# SERDES_10G0 register map
Vendor: Texas Instruments
Registers are 32-bit, access per field, reset 0x0 unless marked. A register's access mark holds for its fields unless they carry their own. Offsets are as the file gives them; [hi:lo] are bit positions.

## SERDES_10G0 (part 6 of 8)
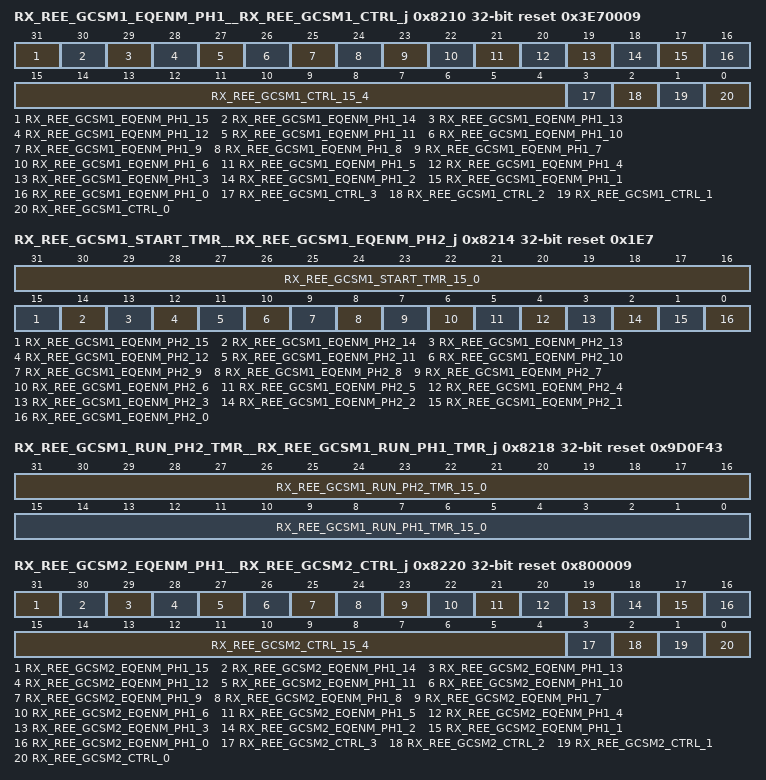
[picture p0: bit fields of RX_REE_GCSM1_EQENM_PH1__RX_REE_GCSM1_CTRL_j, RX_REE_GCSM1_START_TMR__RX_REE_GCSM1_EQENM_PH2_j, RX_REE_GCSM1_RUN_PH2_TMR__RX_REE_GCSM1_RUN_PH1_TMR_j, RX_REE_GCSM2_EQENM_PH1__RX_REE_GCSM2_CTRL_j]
0x8210 RX_REE_GCSM1_EQENM_PH1__RX_REE_GCSM1_CTRL_j reset 0x3E70009 — REE general control state machine 1 control register Offset = 8210h + (j * 400h); where j = 0h to 3h
  [31] RX_REE_GCSM1_EQENM_PH1_15 rw — Reserved - spare
  [30] RX_REE_GCSM1_EQENM_PH1_14 rw — Ignore 1010 controller : When set to 1'b1, this function is enabled when the general control state machine 1 is controlling the REE.
  [29] RX_REE_GCSM1_EQENM_PH1_13 rw — TX equalization evaluator : When set to 1'b1, this function is enabled when the general control state machine 1 is controlling the REE.
  [28] RX_REE_GCSM1_EQENM_PH1_12 rw — TX post cursor control : When set to 1'b1, this function is enabled when the general control state machine 1 is controlling the REE.
  [27] RX_REE_GCSM1_EQENM_PH1_11 rw — TX pre cursor control : When set to 1'b1, this function is enabled when the general control state machine 1 is controlling the REE.
  [26] RX_REE_GCSM1_EQENM_PH1_10 rw — Short channel correction : When set to 1'b1, this function is enabled when the general control state machine 1 is controlling the REE.
  [25] RX_REE_GCSM1_EQENM_PH1_9 rw — RX attenuation : When set to 1'b1, this function is enabled when the general control state machine 1 is controlling the REE.
  [24] RX_REE_GCSM1_EQENM_PH1_8 rw — RX VGA gain : When set to 1'b1, this function is enabled when the general control state machine 1 is controlling the REE.
  [23] RX_REE_GCSM1_EQENM_PH1_7 rw — RX offset correction coefficient : When set to 1'b1, this function is enabled when the general control state machine 1 is controlling the REE.
  [22] RX_REE_GCSM1_EQENM_PH1_6 rw — RX peaking amp gain : When set to 1'b1, this function is enabled when the general control state machine 1 is controlling the REE.
  [21] RX_REE_GCSM1_EQENM_PH1_5 rw — RX low frequency equalizer adaptive control : When set to 1'b1, this function is enabled when the general control state machine 1 is controlling the REE.
  [20] RX_REE_GCSM1_EQENM_PH1_4 rw — Reserved - spare
  [19] RX_REE_GCSM1_EQENM_PH1_3 rw — Reserved - spare
  [18] RX_REE_GCSM1_EQENM_PH1_2 rw — RX tap 3 : When set to 1'b1, this function is enabled when the general control state machine 1 is controlling the REE.
  [17] RX_REE_GCSM1_EQENM_PH1_1 rw — RX tap 2 : When set to 1'b1, this function is enabled when the general control state machine 1 is controlling the REE.
  [16] RX_REE_GCSM1_EQENM_PH1_0 rw — RX tap 1 : When set to 1'b1, this function is enabled when the general control state machine 1 is controlling the REE.
  [15:4] RX_REE_GCSM1_CTRL_15_4 ro — Reserved
  [3] RX_REE_GCSM1_CTRL_3 rw — Equalization function reset enable: Enables the reset of the functions controlled by this state machine, using the rx_ree_fcn_reset_n signal, when the equalization mode changes.
  [2] RX_REE_GCSM1_CTRL_2 rw — Loop enable: Controls when the equalization functions in this state machine are run one time or loop continuously.
  [1] RX_REE_GCSM1_CTRL_1 rw — Force run equalization: Setting this bit to a 1'b1, will force the general control state machine to run, independent of the macro functions that normally run the equalization.
  [0] RX_REE_GCSM1_CTRL_0 rw — Enable: This bit enables the general control state machine function.
0x8214 RX_REE_GCSM1_START_TMR__RX_REE_GCSM1_EQENM_PH2_j rw reset 0x1E7 — REE general control state machine 1 phase 2 equalization enable mask register Offset = 8214h + (j * 400h); where j = 0h to 3h
  [31:16] RX_REE_GCSM1_START_TMR_15_0 — Start timer value : The number of clock cycles the state machine will wait in the Start Delay state.
  [15] RX_REE_GCSM1_EQENM_PH2_15 — Reserved - spare
  [14] RX_REE_GCSM1_EQENM_PH2_14 — Ignore 1010 controller : When set to 1'b1, this function is enabled when the general control state machine 1 is controlling the REE.
  [13] RX_REE_GCSM1_EQENM_PH2_13 — TX equalization evaluator : When set to 1'b1, this function is enabled when the general control state machine 1 is controlling the REE.
  [12] RX_REE_GCSM1_EQENM_PH2_12 — TX post cursor control : When set to 1'b1, this function is enabled when the general control state machine 1 is controlling the REE.
  [11] RX_REE_GCSM1_EQENM_PH2_11 — TX pre cursor control : When set to 1'b1, this function is enabled when the general control state machine 1 is controlling the REE.
  [10] RX_REE_GCSM1_EQENM_PH2_10 — Short channel correction : When set to 1'b1, this function is enabled when the general control state machine 1 is controlling the REE.
  [9] RX_REE_GCSM1_EQENM_PH2_9 — RX attenuation : When set to 1'b1, this function is enabled when the general control state machine 1 is controlling the REE.
  [8] RX_REE_GCSM1_EQENM_PH2_8 — RX VGA gain : When set to 1'b1, this function is enabled when the general control state machine 1 is controlling the REE.
  [7] RX_REE_GCSM1_EQENM_PH2_7 — RX offset correction coefficient : When set to 1'b1, this function is enabled when the general control state machine 1 is controlling the REE.
  [6] RX_REE_GCSM1_EQENM_PH2_6 — RX peaking amp gain : When set to 1'b1, this function is enabled when the general control state machine 1 is controlling the REE.
  [5] RX_REE_GCSM1_EQENM_PH2_5 — RX low frequency equalizer adaptive control : When set to 1'b1, this function is enabled when the general control state machine 1 is controlling the REE.
  [4] RX_REE_GCSM1_EQENM_PH2_4 — Reserved - spare
  [3] RX_REE_GCSM1_EQENM_PH2_3 — Reserved - spare
  [2] RX_REE_GCSM1_EQENM_PH2_2 — RX tap 3 : When set to 1'b1, this function is enabled when the general control state machine 1 is controlling the REE.
  [1] RX_REE_GCSM1_EQENM_PH2_1 — RX tap 2 : When set to 1'b1, this function is enabled when the general control state machine 1 is controlling the REE.
  [0] RX_REE_GCSM1_EQENM_PH2_0 — RX tap 1 : When set to 1'b1, this function is enabled when the general control state machine 1 is controlling the REE.
0x8218 RX_REE_GCSM1_RUN_PH2_TMR__RX_REE_GCSM1_RUN_PH1_TMR_j rw reset 0x9D0F43 — REE general control state machine 1 run phase 1 timer value register Offset = 8218h + (j * 400h); where j = 0h to 3h
  [31:16] RX_REE_GCSM1_RUN_PH2_TMR_15_0 — Run phase 2 timer value : This specifies the number of clock cycles the state machine will wait in the Run Equalization Phase 2 state.
  [15:0] RX_REE_GCSM1_RUN_PH1_TMR_15_0 — Run phase 1 timer value : This specifies the number of clock cycles the state machine will wait in the Run Equalization Phase 1 state.
0x8220 RX_REE_GCSM2_EQENM_PH1__RX_REE_GCSM2_CTRL_j reset 0x800009 — REE general control state machine 2 control register Offset = 8220h + (j * 400h); where j = 0h to 3h
  [31] RX_REE_GCSM2_EQENM_PH1_15 rw — Reserved - spare
  [30] RX_REE_GCSM2_EQENM_PH1_14 rw — Ignore 1010 controller : When set to 1'b1, this function is enabled when the general control state machine 2 is controlling the REE.
  [29] RX_REE_GCSM2_EQENM_PH1_13 rw — TX equalization evaluator : When set to 1'b1, this function is enabled when the general control state machine 2 is controlling the REE.
  [28] RX_REE_GCSM2_EQENM_PH1_12 rw — TX post cursor control : When set to 1'b1, this function is enabled when the general control state machine 2 is controlling the REE.
  [27] RX_REE_GCSM2_EQENM_PH1_11 rw — TX pre cursor control : When set to 1'b1, this function is enabled when the general control state machine 2 is controlling the REE.
  [26] RX_REE_GCSM2_EQENM_PH1_10 rw — Short channel correction : When set to 1'b1, this function is enabled when the general control state machine 2 is controlling the REE.
  [25] RX_REE_GCSM2_EQENM_PH1_9 rw — RX attenuation : When set to 1'b1, this function is enabled when the general control state machine 2 is controlling the REE.
  [24] RX_REE_GCSM2_EQENM_PH1_8 rw — RX VGA gain : When set to 1'b1, this function is enabled when the general control state machine 2 is controlling the REE.
  [23] RX_REE_GCSM2_EQENM_PH1_7 rw — RX offset correction coefficient : When set to 1'b1, this function is enabled when the general control state machine 2 is controlling the REE.
  [22] RX_REE_GCSM2_EQENM_PH1_6 rw — RX peaking amp gain : When set to 1'b1, this function is enabled when the general control state machine 2 is controlling the REE.
  [21] RX_REE_GCSM2_EQENM_PH1_5 rw — RX low frequency equalizer adaptive control : When set to 1'b1, this function is enabled when the general control state machine 2 is controlling the REE.
  [20] RX_REE_GCSM2_EQENM_PH1_4 rw — Reserved - spare
  [19] RX_REE_GCSM2_EQENM_PH1_3 rw — Reserved - spare
  [18] RX_REE_GCSM2_EQENM_PH1_2 rw — RX tap 3 : When set to 1'b1, this function is enabled when the general control state machine 2 is controlling the REE.
  [17] RX_REE_GCSM2_EQENM_PH1_1 rw — RX tap 2 : When set to 1'b1, this function is enabled when the general control state machine 2 is controlling the REE.
  [16] RX_REE_GCSM2_EQENM_PH1_0 rw — RX tap 1 : When set to 1'b1, this function is enabled when the general control state machine 2 is controlling the REE.
  [15:4] RX_REE_GCSM2_CTRL_15_4 ro — Reserved
  [3] RX_REE_GCSM2_CTRL_3 rw — Equalization function reset enable: Enables the reset of the functions controlled by this state machine, using the rx_ree_fcn_reset_n signal, when the equalization mode changes.
  [2] RX_REE_GCSM2_CTRL_2 rw — Loop enable: Controls when the equalization functions in this state machine are run one time or loop continuously.
  [1] RX_REE_GCSM2_CTRL_1 rw — Force run equalization: Setting this bit to a 1'b1, will force the general control state machine to run, independent of the macro functions that normally run the equalization.
  [0] RX_REE_GCSM2_CTRL_0 rw — Enable: This bit enables the general control state machine function.
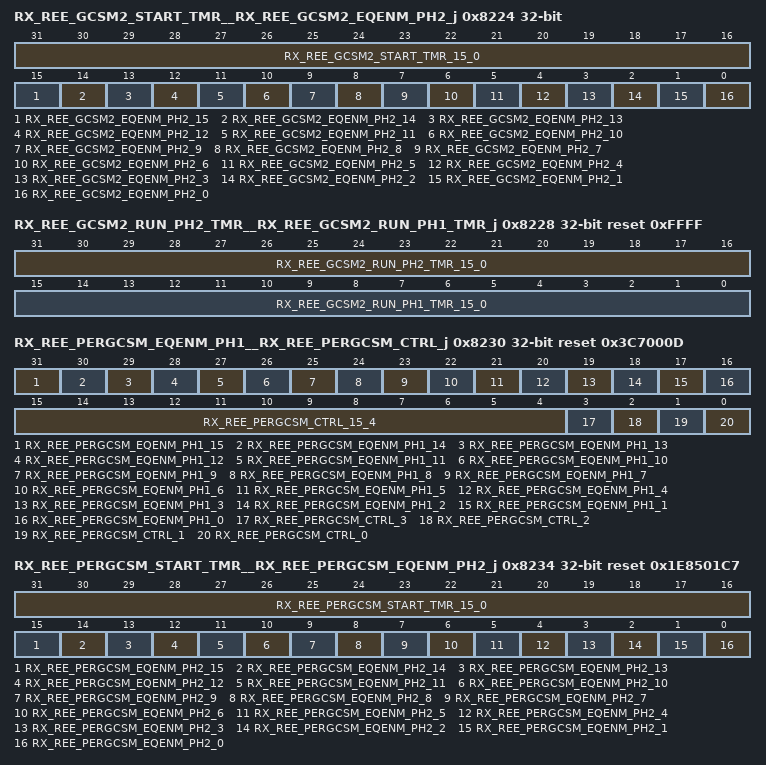
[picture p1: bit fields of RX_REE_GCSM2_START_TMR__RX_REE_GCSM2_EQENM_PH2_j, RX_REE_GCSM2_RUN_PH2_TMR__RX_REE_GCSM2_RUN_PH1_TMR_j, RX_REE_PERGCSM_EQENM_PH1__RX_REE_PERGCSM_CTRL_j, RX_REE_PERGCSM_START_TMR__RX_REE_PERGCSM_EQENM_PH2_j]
0x8224 RX_REE_GCSM2_START_TMR__RX_REE_GCSM2_EQENM_PH2_j rw — REE general control state machine 2 phase 2 equalization enable mask register Offset = 8224h + (j * 400h); where j = 0h to 3h
  [31:16] RX_REE_GCSM2_START_TMR_15_0 — Start timer value : The number of clock cycles the state machine will wait in the Start Delay state.
  [15] RX_REE_GCSM2_EQENM_PH2_15 — Reserved - spare
  [14] RX_REE_GCSM2_EQENM_PH2_14 — Ignore 1010 controller : When set to 1'b1, this function is enabled when the general control state machine 2 is controlling the REE.
  [13] RX_REE_GCSM2_EQENM_PH2_13 — TX equalization evaluator : When set to 1'b1, this function is enabled when the general control state machine 2 is controlling the REE.
  [12] RX_REE_GCSM2_EQENM_PH2_12 — TX post cursor control : When set to 1'b1, this function is enabled when the general control state machine 2 is controlling the REE.
  [11] RX_REE_GCSM2_EQENM_PH2_11 — TX pre cursor control : When set to 1'b1, this function is enabled when the general control state machine 2 is controlling the REE.
  [10] RX_REE_GCSM2_EQENM_PH2_10 — Short channel correction : When set to 1'b1, this function is enabled when the general control state machine 2 is controlling the REE.
  [9] RX_REE_GCSM2_EQENM_PH2_9 — RX attenuation : When set to 1'b1, this function is enabled when the general control state machine 2 is controlling the REE.
  [8] RX_REE_GCSM2_EQENM_PH2_8 — RX VGA gain : When set to 1'b1, this function is enabled when the general control state machine 2 is controlling the REE.
  [7] RX_REE_GCSM2_EQENM_PH2_7 — RX offset correction coefficient : When set to 1'b1, this function is enabled when the general control state machine 2 is controlling the REE.
  [6] RX_REE_GCSM2_EQENM_PH2_6 — RX peaking amp gain : When set to 1'b1, this function is enabled when the general control state machine 2 is controlling the REE.
  [5] RX_REE_GCSM2_EQENM_PH2_5 — RX low frequency equalizer adaptive control : When set to 1'b1, this function is enabled when the general control state machine 2 is controlling the REE.
  [4] RX_REE_GCSM2_EQENM_PH2_4 — Reserved - spare
  [3] RX_REE_GCSM2_EQENM_PH2_3 — Reserved - spare
  [2] RX_REE_GCSM2_EQENM_PH2_2 — RX tap 3 : When set to 1'b1, this function is enabled when the general control state machine 2 is controlling the REE.
  [1] RX_REE_GCSM2_EQENM_PH2_1 — RX tap 2 : When set to 1'b1, this function is enabled when the general control state machine 2 is controlling the REE.
  [0] RX_REE_GCSM2_EQENM_PH2_0 — RX tap 1 : When set to 1'b1, this function is enabled when the general control state machine 2 is controlling the REE.
0x8228 RX_REE_GCSM2_RUN_PH2_TMR__RX_REE_GCSM2_RUN_PH1_TMR_j rw reset 0xFFFF — REE general control state machine 2 run phase 1 timer value register Offset = 8228h + (j * 400h); where j = 0h to 3h
  [31:16] RX_REE_GCSM2_RUN_PH2_TMR_15_0 — Run phase 2 timer value : This specifies the number of clock cycles the state machine will wait in the Run Equalization Phase 2 state.
  [15:0] RX_REE_GCSM2_RUN_PH1_TMR_15_0 — Run phase 1 timer value : This specifies the number of clock cycles the state machine will wait in the Run Equalization Phase 1 state.
0x8230 RX_REE_PERGCSM_EQENM_PH1__RX_REE_PERGCSM_CTRL_j reset 0x3C7000D — REE periodic general control state machine control register Offset = 8230h + (j * 400h); where j = 0h to 3h
  [31] RX_REE_PERGCSM_EQENM_PH1_15 rw — Reserved - spare
  [30] RX_REE_PERGCSM_EQENM_PH1_14 rw — Ignore 1010 controller : When set to 1'b1, this function is enabled when the periodic general control state machine is controlling the REE.
  [29] RX_REE_PERGCSM_EQENM_PH1_13 rw — TX equalization evaluator : When set to 1'b1, this function is enabled when the periodic general control state machine is controlling the REE.
  [28] RX_REE_PERGCSM_EQENM_PH1_12 rw — TX post cursor control : When set to 1'b1, this function is enabled when the periodic general control state machine is controlling the REE.
  [27] RX_REE_PERGCSM_EQENM_PH1_11 rw — TX pre cursor control : When set to 1'b1, this function is enabled when the periodic general control state machine is controlling the REE.
  [26] RX_REE_PERGCSM_EQENM_PH1_10 rw — Short channel correction : When set to 1'b1, this function is enabled when the periodic general control state machine is controlling the REE.
  [25] RX_REE_PERGCSM_EQENM_PH1_9 rw — RX attenuation : When set to 1'b1, this function is enabled when the periodic general control state machine is controlling the REE.
  [24] RX_REE_PERGCSM_EQENM_PH1_8 rw — RX VGA gain : When set to 1'b1, this function is enabled when the periodic general control state machine is controlling the REE.
  [23] RX_REE_PERGCSM_EQENM_PH1_7 rw — RX offset correction coefficient : When set to 1'b1, this function is enabled when the periodic general control state machine is controlling the REE.
  [22] RX_REE_PERGCSM_EQENM_PH1_6 rw — RX peaking amp gain : When set to 1'b1, this function is enabled when the periodic general control state machine is controlling the REE.
  [21] RX_REE_PERGCSM_EQENM_PH1_5 rw — RX low frequency equalizer adaptive control : When set to 1'b1, this function is enabled when the periodic general control state machine is controlling the REE.
  [20] RX_REE_PERGCSM_EQENM_PH1_4 rw — Reserved - spare
  [19] RX_REE_PERGCSM_EQENM_PH1_3 rw — Reserved - spare
  [18] RX_REE_PERGCSM_EQENM_PH1_2 rw — RX tap 3 : When set to 1'b1, this function is enabled when the periodic general control state machine is controlling the REE.
  [17] RX_REE_PERGCSM_EQENM_PH1_1 rw — RX tap 2 : When set to 1'b1, this function is enabled when the periodic general control state machine is controlling the REE.
  [16] RX_REE_PERGCSM_EQENM_PH1_0 rw — RX tap 1 : When set to 1'b1, this function is enabled when the periodic general control state machine is controlling the REE.
  [15:4] RX_REE_PERGCSM_CTRL_15_4 ro — Reserved
  [3] RX_REE_PERGCSM_CTRL_3 rw — Equalization function reset enable: Enables the reset of the functions controlled by this state machine, using the rx_ree_fcn_reset_n pin, when the equalization mode changes.
  [2] RX_REE_PERGCSM_CTRL_2 rw — Loop enable: Controls when the equalization functions in this state machine are run one time or loop continuously.
  [1] RX_REE_PERGCSM_CTRL_1 rw — Force run equalization: Setting this bit to a 1'b1, will force the general control state machine to run, independent of the macro functions that normally run the equalization.
  [0] RX_REE_PERGCSM_CTRL_0 rw — Enable: This bit enables the general control state machine function.
0x8234 RX_REE_PERGCSM_START_TMR__RX_REE_PERGCSM_EQENM_PH2_j rw reset 0x1E8501C7 — REE periodic general control state machine phase 2 equalization enable mask register Offset = 8234h + (j * 400h); where j = 0h to 3h
  [31:16] RX_REE_PERGCSM_START_TMR_15_0 — Start timer value : The number of clock cycles the state machine will wait in the Start Delay state.
  [15] RX_REE_PERGCSM_EQENM_PH2_15 — Reserved - spare
  [14] RX_REE_PERGCSM_EQENM_PH2_14 — Ignore 1010 controller : When set to 1'b1, this function is enabled when the periodic general control state machine is controlling the REE.
  [13] RX_REE_PERGCSM_EQENM_PH2_13 — TX equalization evaluator : When set to 1'b1, this function is enabled when the periodic general control state machine is controlling the REE.
  [12] RX_REE_PERGCSM_EQENM_PH2_12 — TX post cursor control : When set to 1'b1, this function is enabled when the periodic general control state machine is controlling the REE.
  [11] RX_REE_PERGCSM_EQENM_PH2_11 — TX pre cursor control : When set to 1'b1, this function is enabled when the periodic general control state machine is controlling the REE.
  [10] RX_REE_PERGCSM_EQENM_PH2_10 — Short channel correction : When set to 1'b1, this function is enabled when the periodic general control state machine is controlling the REE.
  [9] RX_REE_PERGCSM_EQENM_PH2_9 — RX attenuation : When set to 1'b1, this function is enabled when the periodic general control state machine is controlling the REE.
  [8] RX_REE_PERGCSM_EQENM_PH2_8 — RX VGA gain : When set to 1'b1, this function is enabled when the periodic general control state machine is controlling the REE.
  [7] RX_REE_PERGCSM_EQENM_PH2_7 — RX offset correction coefficient : When set to 1'b1, this function is enabled when the periodic general control state machine is controlling the REE.
  [6] RX_REE_PERGCSM_EQENM_PH2_6 — RX peaking amp gain : When set to 1'b1, this function is enabled when the periodic general control state machine is controlling the REE.
  [5] RX_REE_PERGCSM_EQENM_PH2_5 — RX low frequency equalizer adaptive control : When set to 1'b1, this function is enabled when the periodic general control state machine is controlling the REE.
  [4] RX_REE_PERGCSM_EQENM_PH2_4 — Reserved - spare
  [3] RX_REE_PERGCSM_EQENM_PH2_3 — Reserved - spare
  [2] RX_REE_PERGCSM_EQENM_PH2_2 — RX tap 3 : When set to 1'b1, this function is enabled when the periodic general control state machine is controlling the REE.
  [1] RX_REE_PERGCSM_EQENM_PH2_1 — RX tap 2 : When set to 1'b1, this function is enabled when the periodic general control state machine is controlling the REE.
  [0] RX_REE_PERGCSM_EQENM_PH2_0 — RX tap 1 : When set to 1'b1, this function is enabled when the periodic general control state machine is controlling the REE.
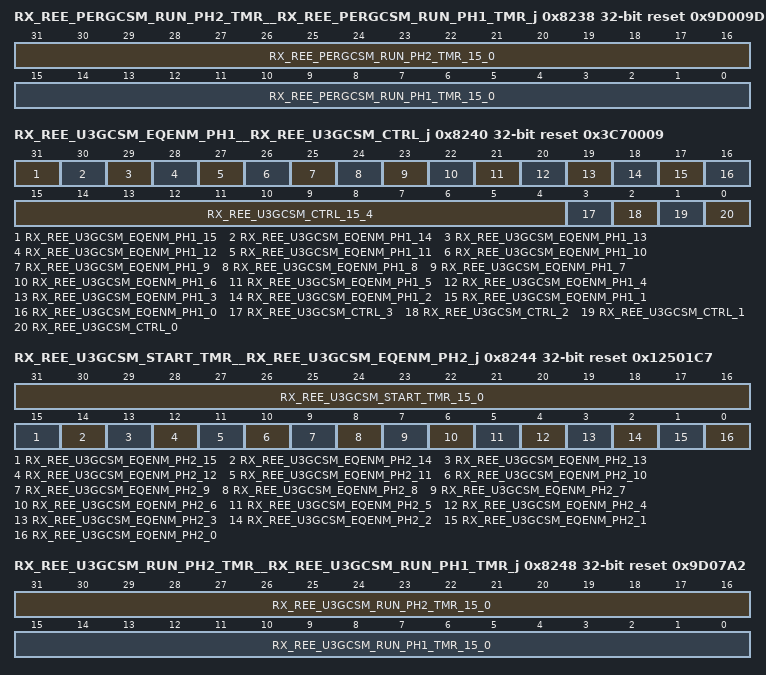
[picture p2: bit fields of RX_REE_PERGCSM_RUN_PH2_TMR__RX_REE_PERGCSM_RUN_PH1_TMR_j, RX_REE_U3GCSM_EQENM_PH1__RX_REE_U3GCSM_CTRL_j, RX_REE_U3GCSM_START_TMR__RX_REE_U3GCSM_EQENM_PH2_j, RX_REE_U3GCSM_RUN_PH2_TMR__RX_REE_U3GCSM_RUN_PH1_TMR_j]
0x8238 RX_REE_PERGCSM_RUN_PH2_TMR__RX_REE_PERGCSM_RUN_PH1_TMR_j rw reset 0x9D009D — REE periodic general control state machine run phase 1 timer value register Offset = 8238h + (j * 400h); where j = 0h to 3h
  [31:16] RX_REE_PERGCSM_RUN_PH2_TMR_15_0 — Run phase 2 timer value : This specifies the number of clock cycles the state machine will wait in the Run Equalization Phase 2 state.
  [15:0] RX_REE_PERGCSM_RUN_PH1_TMR_15_0 — Run phase 1 timer value : This specifies the number of clock cycles the state machine will wait in the Run Equalization Phase 1 state.
0x8240 RX_REE_U3GCSM_EQENM_PH1__RX_REE_U3GCSM_CTRL_j reset 0x3C70009 — REE USB 3 general control state machine control register Offset = 8240h + (j * 400h); where j = 0h to 3h
  [31] RX_REE_U3GCSM_EQENM_PH1_15 rw — Reserved - spare
  [30] RX_REE_U3GCSM_EQENM_PH1_14 rw — Ignore 1010 controller : When set to 1'b1, this function is enabled when the USB 3.0 general control state machine is controlling the REE.
  [29] RX_REE_U3GCSM_EQENM_PH1_13 rw — TX equalization evaluator : When set to 1'b1, this function is enabled when the USB 3.0 general control state machine is controlling the REE.
  [28] RX_REE_U3GCSM_EQENM_PH1_12 rw — TX post cursor control : When set to 1'b1, this function is enabled when the USB 3.0 general control state machine is controlling the REE.
  [27] RX_REE_U3GCSM_EQENM_PH1_11 rw — TX pre cursor control : When set to 1'b1, this function is enabled when the USB 3.0 general control state machine is controlling the REE.
  [26] RX_REE_U3GCSM_EQENM_PH1_10 rw — Short channel correction : When set to 1'b1, this function is enabled when the USB 3.0 general control state machine is controlling the REE.
  [25] RX_REE_U3GCSM_EQENM_PH1_9 rw — RX attenuation : When set to 1'b1, this function is enabled when the USB 3.0 general control state machine is controlling the REE.
  [24] RX_REE_U3GCSM_EQENM_PH1_8 rw — RX VGA gain : When set to 1'b1, this function is enabled when the USB 3.0 general control state machine is controlling the REE.
  [23] RX_REE_U3GCSM_EQENM_PH1_7 rw — RX offset correction coefficient : When set to 1'b1, this function is enabled when the USB 3.0 general control state machine is controlling the REE.
  [22] RX_REE_U3GCSM_EQENM_PH1_6 rw — RX peaking amp gain : When set to 1'b1, this function is enabled when the USB 3.0 general control state machine is controlling the REE.
  [21] RX_REE_U3GCSM_EQENM_PH1_5 rw — RX low frequency equalizer adaptive control : When set to 1'b1, this function is enabled when the USB 3.0 general control state machine is controlling the REE.
  [20] RX_REE_U3GCSM_EQENM_PH1_4 rw — Reserved - spare
  [19] RX_REE_U3GCSM_EQENM_PH1_3 rw — Reserved - spare
  [18] RX_REE_U3GCSM_EQENM_PH1_2 rw — RX tap 3 : When set to 1'b1, this function is enabled when the USB 3.0 general control state machine is controlling the REE.
  [17] RX_REE_U3GCSM_EQENM_PH1_1 rw — RX tap 2 : When set to 1'b1, this function is enabled when the USB 3.0 general control state machine is controlling the REE.
  [16] RX_REE_U3GCSM_EQENM_PH1_0 rw — RX tap 1 : When set to 1'b1, this function is enabled when the USB 3.0 general control state machine is controlling the REE.
  [15:4] RX_REE_U3GCSM_CTRL_15_4 ro — Reserved
  [3] RX_REE_U3GCSM_CTRL_3 rw — Equalization function reset enable: Enables the reset of the functions controlled by this state machine, using the rx_ree_fcn_reset_n pin, when the equalization mode changes.
  [2] RX_REE_U3GCSM_CTRL_2 rw — Loop enable: Controls when the equalization functions in this state machine are run one time or loop continuously.
  [1] RX_REE_U3GCSM_CTRL_1 rw — Force run equalization: Setting this bit to a 1'b1, will force the general control state machine to run, independent of the macro functions that normally run the equalization.
  [0] RX_REE_U3GCSM_CTRL_0 rw — Enable: This bit enables the general control state machine function.
0x8244 RX_REE_U3GCSM_START_TMR__RX_REE_U3GCSM_EQENM_PH2_j rw reset 0x12501C7 — REE USB 3 general control state machine phase 2 equalization enable mask register Offset = 8244h + (j * 400h); where j = 0h to 3h
  [31:16] RX_REE_U3GCSM_START_TMR_15_0 — Start timer value : The number of clock cycles the state machine will wait in the Start Delay state.
  [15] RX_REE_U3GCSM_EQENM_PH2_15 — Reserved - spare
  [14] RX_REE_U3GCSM_EQENM_PH2_14 — Ignore 1010 controller : When set to 1'b1, this function is enabled when the USB 3.0 general control state machine is controlling the REE.
  [13] RX_REE_U3GCSM_EQENM_PH2_13 — TX equalization evaluator : When set to 1'b1, this function is enabled when the USB 3.0 general control state machine is controlling the REE.
  [12] RX_REE_U3GCSM_EQENM_PH2_12 — TX post cursor control : When set to 1'b1, this function is enabled when the USB 3.0 general control state machine is controlling the REE.
  [11] RX_REE_U3GCSM_EQENM_PH2_11 — TX pre cursor control : When set to 1'b1, this function is enabled when the USB 3.0 general control state machine is controlling the REE.
  [10] RX_REE_U3GCSM_EQENM_PH2_10 — Short channel correction : When set to 1'b1, this function is enabled when the USB 3.0 general control state machine is controlling the REE.
  [9] RX_REE_U3GCSM_EQENM_PH2_9 — RX attenuation : When set to 1'b1, this function is enabled when the USB 3.0 general control state machine is controlling the REE.
  [8] RX_REE_U3GCSM_EQENM_PH2_8 — RX VGA gain : When set to 1'b1, this function is enabled when the USB 3.0 general control state machine is controlling the REE.
  [7] RX_REE_U3GCSM_EQENM_PH2_7 — RX offset correction coefficient : When set to 1'b1, this function is enabled when the USB 3.0 general control state machine is controlling the REE.
  [6] RX_REE_U3GCSM_EQENM_PH2_6 — RX peaking amp gain : When set to 1'b1, this function is enabled when the USB 3.0 general control state machine is controlling the REE.
  [5] RX_REE_U3GCSM_EQENM_PH2_5 — RX low frequency equalizer adaptive control : When set to 1'b1, this function is enabled when the USB 3.0 general control state machine is controlling the REE.
  [4] RX_REE_U3GCSM_EQENM_PH2_4 — Reserved - spare
  [3] RX_REE_U3GCSM_EQENM_PH2_3 — Reserved - spare
  [2] RX_REE_U3GCSM_EQENM_PH2_2 — RX tap 3 : When set to 1'b1, this function is enabled when the USB 3.0 general control state machine is controlling the REE.
  [1] RX_REE_U3GCSM_EQENM_PH2_1 — RX tap 2 : When set to 1'b1, this function is enabled when the USB 3.0 general control state machine is controlling the REE.
  [0] RX_REE_U3GCSM_EQENM_PH2_0 — RX tap 1 : When set to 1'b1, this function is enabled when the USB 3.0 general control state machine is controlling the REE.
0x8248 RX_REE_U3GCSM_RUN_PH2_TMR__RX_REE_U3GCSM_RUN_PH1_TMR_j rw reset 0x9D07A2 — REE USB 3 general control state machine run phase 1 timer value register Offset = 8248h + (j * 400h); where j = 0h to 3h
  [31:16] RX_REE_U3GCSM_RUN_PH2_TMR_15_0 — Run phase 2 timer value : This specifies the number of clock cycles the state machine will wait in the Run Equalization Phase 2 state.
  [15:0] RX_REE_U3GCSM_RUN_PH1_TMR_15_0 — Run phase 1 timer value : This specifies the number of clock cycles the state machine will wait in the Run Equalization Phase 1 state.
0x8250 RX_REE_ANAENSM_DEL_TMR_j rw reset 0x64 — REE analog enable control state machine delay timer value register Offset = 8250h + (j * 400h); where j = 0h to 3h
  [15:0] RX_REE_ANAENSM_DEL_TMR_15_0 — Analog enable delay timer value : The number of clock cycles the state machine will wait in the Analog Enable Delay state.
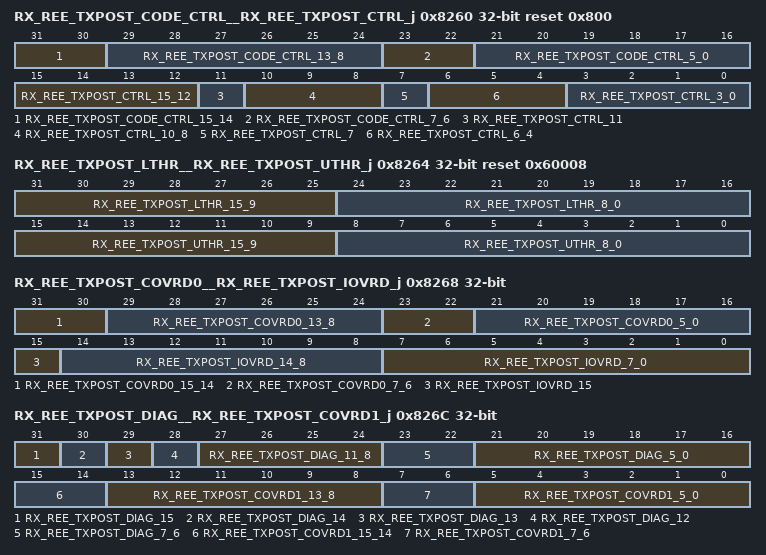
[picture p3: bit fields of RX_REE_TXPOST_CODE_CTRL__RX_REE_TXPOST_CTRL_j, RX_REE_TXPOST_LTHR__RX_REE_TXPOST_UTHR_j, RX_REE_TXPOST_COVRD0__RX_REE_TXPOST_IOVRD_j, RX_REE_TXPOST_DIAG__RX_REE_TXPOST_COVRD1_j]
0x8260 RX_REE_TXPOST_CODE_CTRL__RX_REE_TXPOST_CTRL_j reset 0x800 — REE TX post cursor control register Offset = 8260h + (j * 400h); where j = 0h to 3h
  [31:30] RX_REE_TXPOST_CODE_CTRL_15_14 ro — Reserved
  [29:24] RX_REE_TXPOST_CODE_CTRL_13_8 rw — Peaking amp code maximum value: This is the maximum value that the peaking amp code will be allowed to increase to.
  [23:22] RX_REE_TXPOST_CODE_CTRL_7_6 ro — Reserved
  [21:16] RX_REE_TXPOST_CODE_CTRL_5_0 rw — Peaking amp initial code: Initial value the peaking amp code is set to when training starts.
  [15:12] RX_REE_TXPOST_CTRL_15_12 ro — Reserved
  [11] RX_REE_TXPOST_CTRL_11 rw — Peaking amp feedback path enable: Enables the peaking amp feedback path.
  [10:8] RX_REE_TXPOST_CTRL_10_8 rw — Peaking amp feedback scaler value: Specifies the amount to scale the peaking amp feedback by.
  [7] RX_REE_TXPOST_CTRL_7 ro — Reserved
  [6:4] RX_REE_TXPOST_CTRL_6_4 rw — Peaking amp integrator accumulator scaler value: Specifies the amount to scale the input to the peaking amp integrator accumulator by.
  [3:0] RX_REE_TXPOST_CTRL_3_0 rw — Peaking amp sigma delta accumulator scaler value: Specifies the amount to scale the input to the peaking amp sigma delta accumulator by.
0x8264 RX_REE_TXPOST_LTHR__RX_REE_TXPOST_UTHR_j reset 0x60008 — REE TX post cursor upper threshold register Offset = 8264h + (j * 400h); where j = 0h to 3h
  [31:25] RX_REE_TXPOST_LTHR_15_9 ro — Reserved
  [24:16] RX_REE_TXPOST_LTHR_8_0 rw — Peaking amp algorithm lower threshold: This is the lower threshold value used in the peaking amp algorithm.
  [15:9] RX_REE_TXPOST_UTHR_15_9 ro — Reserved
  [8:0] RX_REE_TXPOST_UTHR_8_0 rw — Peaking amp algorithm upper threshold: This is the upper threshold value used in the peaking amp algorithm.
0x8268 RX_REE_TXPOST_COVRD0__RX_REE_TXPOST_IOVRD_j — REE TX post cursor input override register Offset = 8268h + (j * 400h); where j = 0h to 3h
  [31:30] RX_REE_TXPOST_COVRD0_15_14 ro — Reserved
  [29:24] RX_REE_TXPOST_COVRD0_13_8 rw — Peaking amp code override value mode 1: Value that will override the peaking amp code when in standard mode 1 when the peaking amp code override enable bit in the REE TX post cursor diagnostics register on page 259 is active.
  [23:22] RX_REE_TXPOST_COVRD0_7_6 ro — Reserved
  [21:16] RX_REE_TXPOST_COVRD0_5_0 rw — Peaking amp code override value mode 0: Value that will override the peaking amp code when in standard mode 0 when the peaking amp code override enable bit in the REE TX post cursor diagnostics register on page 259 is active.
  [15] RX_REE_TXPOST_IOVRD_15 rw — Peaking amp tap accumulator input override enable: Setting this bit to a 1'b1 will allow the tap accumulator input in the peaking amp gain algorithm to be overridden by the peaking amp tap accumulator input override field in this register.
  [14:8] RX_REE_TXPOST_IOVRD_14_8 ro — Reserved
  [7:0] RX_REE_TXPOST_IOVRD_7_0 rw — Peaking amp tap accumulator input override : Value that will override the tap accumulator input in the peaking amp gain algorithm, when the Peaking amp tap accumulator input override enable bit is active.
0x826C RX_REE_TXPOST_DIAG__RX_REE_TXPOST_COVRD1_j — REE TX post cursor code override 1 register Offset = 826Ch + (j * 400h); where j = 0h to 3h
  [31] RX_REE_TXPOST_DIAG_15 rw — Peaking amp code override enable: Setting this bit to a 1'b1 will allow the peaking amp code to be overridden by the peaking amp code override value fields in the REE TX post cursor code override 0 register on page 258 and REE TX post cursor code override 1 register on page 259.
  [30] RX_REE_TXPOST_DIAG_14 rw — Voter override neg : Writing a 1'b1 in this register bit will force the peaking amp voter function to activate the voter neg signal for a single clock cycle.
  [29] RX_REE_TXPOST_DIAG_13 rw — Voter override pos : Writing a 1'b1 in this register bit will force the peaking amp voter function to activate the voter pos signal for a single clock cycle.
  [28] RX_REE_TXPOST_DIAG_12 rw — Voter override enable : Setting this bit to a 1'b1 will allow only the voter override pos and voter override neg bits in this register to control the voter in the peaking amp.
  [27:24] RX_REE_TXPOST_DIAG_11_8 ro — Reserved
  [23:22] RX_REE_TXPOST_DIAG_7_6 ro — Reserved
  [21:16] RX_REE_TXPOST_DIAG_5_0 ro — Current peaking amp integrator accumulator: Current value of the tap integrator accumulator, without the unused sign bit.
  [15:14] RX_REE_TXPOST_COVRD1_15_14 ro — Reserved
  [13:8] RX_REE_TXPOST_COVRD1_13_8 rw — Peaking amp code override value mode 3: Value that will override the peaking amp code when in standard mode 3 when the peaking amp code override enable bit in the REE TX post cursor diagnostics register on page 259 is active.
  [7:6] RX_REE_TXPOST_COVRD1_7_6 ro — Reserved
  [5:0] RX_REE_TXPOST_COVRD1_5_0 rw — Peaking amp code override value mode 2: Value that will override the peaking amp code when in standard mode 2 when the peaking amp code override enable bit in the REE TX post cursor diagnostics register on page 259 is active.
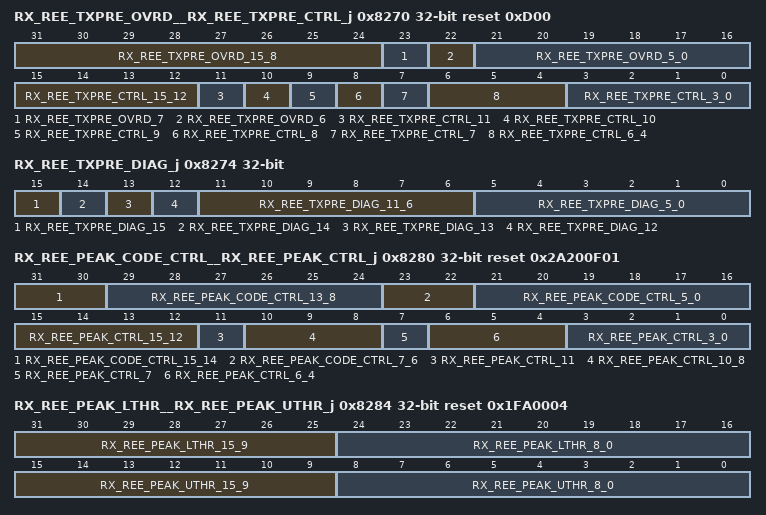
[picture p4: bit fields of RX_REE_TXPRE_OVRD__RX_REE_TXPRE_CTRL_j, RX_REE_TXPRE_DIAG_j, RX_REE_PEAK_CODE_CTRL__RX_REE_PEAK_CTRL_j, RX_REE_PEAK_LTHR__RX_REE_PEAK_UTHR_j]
0x8270 RX_REE_TXPRE_OVRD__RX_REE_TXPRE_CTRL_j reset 0xD00 — REE TX pre cursor control register Offset = 8270h + (j * 400h); where j = 0h to 3h
  [31:24] RX_REE_TXPRE_OVRD_15_8 ro — Reserved
  [23] RX_REE_TXPRE_OVRD_7 rw — Tap override enable: Setting this bit to a 1'b1 will enable the tap override field in this register to override the tap integrator accumulator functions.
  [22] RX_REE_TXPRE_OVRD_6 ro — Reserved
  [21:16] RX_REE_TXPRE_OVRD_5_0 rw — Tap override value: When the tap override enable bit in this register is active, the value in this field will override the integrator accumulator value, as well as the input to the binary to thermometer encoder.
  [15:12] RX_REE_TXPRE_CTRL_15_12 ro — Reserved
  [11] RX_REE_TXPRE_CTRL_11 rw — Tap coefficient combinational logic zero crossing enable:
  [10] RX_REE_TXPRE_CTRL_10 rw — Tap coefficient combinational logic non zero crossing enable:
  [9] RX_REE_TXPRE_CTRL_9 rw — Tap coefficient combinational logic bit 0 only enable:
  [8] RX_REE_TXPRE_CTRL_8 rw — Receiver DFE tap coefficient disable: This bit disables the rxda_dfe_tap_coef output signal.
  [7] RX_REE_TXPRE_CTRL_7 ro — Reserved
  [6:4] RX_REE_TXPRE_CTRL_6_4 rw — Tap integrator accumulator scaler value: Specifies the amount to scale the input to the tap integrator accumulator by.
  [3:0] RX_REE_TXPRE_CTRL_3_0 rw — Tap sigma delta accumulator scaler value: Specifies the amount to scale the input to the tap sigma delta accumulator by.
0x8274 RX_REE_TXPRE_DIAG_j — REE TX pre cursor diagnostics register Offset = 8274h + (j * 400h); where j = 0h to 3h
  [15] RX_REE_TXPRE_DIAG_15 ro — Reserved
  [14] RX_REE_TXPRE_DIAG_14 rw — Voter override neg : Writing a 1'b1 in this register bit will force the tap voter function to activate the voter neg signal for a single clock cycle.
  [13] RX_REE_TXPRE_DIAG_13 rw — Voter override pos : Writing a 1'b1 in this register bit will force the tap voter function to activate the voter pos signal for a single clock cycle.
  [12] RX_REE_TXPRE_DIAG_12 rw — Voter override enable : Setting this bit to a 1'b1 will allow only the voter override pos and voter override neg bits in this register to control the voter in the tap.
  [11:6] RX_REE_TXPRE_DIAG_11_6 ro — Reserved
  [5:0] RX_REE_TXPRE_DIAG_5_0 ro — Current tap integrator accumulator: Current value of the tap integrator accumulator.
0x8280 RX_REE_PEAK_CODE_CTRL__RX_REE_PEAK_CTRL_j reset 0x2A200F01 — REE peaking amp control register Offset = 8280h + (j * 400h); where j = 0h to 3h
  [31:30] RX_REE_PEAK_CODE_CTRL_15_14 ro — Reserved
  [29:24] RX_REE_PEAK_CODE_CTRL_13_8 rw — Peaking amp code maximum value: This is the maximum value that the peaking amp code will be allowed to increase to.
  [23:22] RX_REE_PEAK_CODE_CTRL_7_6 ro — Reserved
  [21:16] RX_REE_PEAK_CODE_CTRL_5_0 rw — Peaking amp initial code: Initial value the peaking amp code is set to when training starts.
  [15:12] RX_REE_PEAK_CTRL_15_12 ro — Reserved
  [11] RX_REE_PEAK_CTRL_11 rw — Peaking amp feedback path enable: Enables the peaking amp feedback path.
  [10:8] RX_REE_PEAK_CTRL_10_8 rw — Peaking amp feedback scaler value: Specifies the amount to scale the peaking amp feedback by.
  [7] RX_REE_PEAK_CTRL_7 ro — Reserved
  [6:4] RX_REE_PEAK_CTRL_6_4 rw — Peaking amp integrator accumulator scaler value: Specifies the amount to scale the input to the peaking amp integrator accumulator by.
  [3:0] RX_REE_PEAK_CTRL_3_0 rw — Peaking amp sigma delta accumulator scaler value: Specifies the amount to scale the input to the peaking amp sigma delta accumulator by.
0x8284 RX_REE_PEAK_LTHR__RX_REE_PEAK_UTHR_j reset 0x1FA0004 — REE peaking amp upper threshold register Offset = 8284h + (j * 400h); where j = 0h to 3h
  [31:25] RX_REE_PEAK_LTHR_15_9 ro — Reserved
  [24:16] RX_REE_PEAK_LTHR_8_0 rw — Peaking amp algorithm lower threshold: This is the lower threshold value used in the peaking amp algorithm.
  [15:9] RX_REE_PEAK_UTHR_15_9 ro — Reserved
  [8:0] RX_REE_PEAK_UTHR_8_0 rw — Peaking amp algorithm upper threshold: This is the upper threshold value used in the peaking amp algorithm.
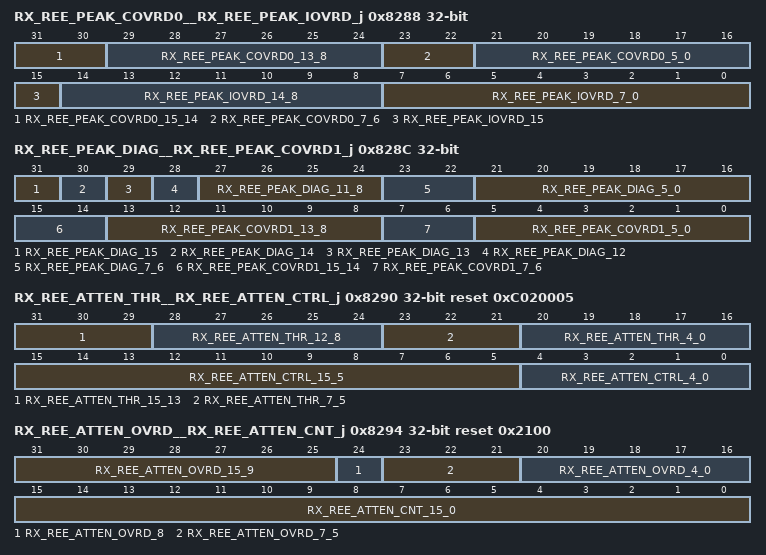
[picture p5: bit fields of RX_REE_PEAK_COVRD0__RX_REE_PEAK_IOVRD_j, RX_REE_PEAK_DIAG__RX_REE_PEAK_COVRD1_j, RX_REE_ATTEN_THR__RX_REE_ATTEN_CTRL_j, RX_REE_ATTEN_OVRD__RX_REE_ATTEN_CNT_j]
0x8288 RX_REE_PEAK_COVRD0__RX_REE_PEAK_IOVRD_j — REE peaking amp input override register Offset = 8288h + (j * 400h); where j = 0h to 3h
  [31:30] RX_REE_PEAK_COVRD0_15_14 ro — Reserved
  [29:24] RX_REE_PEAK_COVRD0_13_8 rw — Peaking amp code override value mode 1: Value that will override the peaking amp code when in standard mode 1 when the peaking amp code override enable bit in the REE peaking amp diagnostics register on page 264 is active.
  [23:22] RX_REE_PEAK_COVRD0_7_6 ro — Reserved
  [21:16] RX_REE_PEAK_COVRD0_5_0 rw — Peaking amp code override value mode 0: Value that will override the peaking amp code when in standard mode 0 when the peaking amp code override enable bit in the REE peaking amp diagnostics register on page 264 is active.
  [15] RX_REE_PEAK_IOVRD_15 rw — Peaking amp tap accumulator input override enable: Setting this bit to a 1'b1 will allow the tap accumulator input in the peaking amp gain algorithm to be overridden by the peaking amp tap accumulator input override field in this register.
  [14:8] RX_REE_PEAK_IOVRD_14_8 ro — Reserved
  [7:0] RX_REE_PEAK_IOVRD_7_0 rw — Peaking amp tap accumulator input override : Value that will override the tap accumulator input in the peaking amp gain algorithm, when the Peaking amp tap accumulator input override enable bit is active.
0x828C RX_REE_PEAK_DIAG__RX_REE_PEAK_COVRD1_j — REE peaking amp code override 1 register Offset = 828Ch + (j * 400h); where j = 0h to 3h
  [31] RX_REE_PEAK_DIAG_15 rw — Peaking amp code override enable: Setting this bit to a 1'b1 will allow the peaking amp code to be overridden by the peaking amp code override value fields in the REE peaking amp code override 0 register on page 263 and REE peaking amp code override 1 register on page 263.
  [30] RX_REE_PEAK_DIAG_14 rw — Voter override neg : Writing a 1'b1 in this register bit will force the peaking amp voter function to activate the voter neg signal for a single clock cycle.
  [29] RX_REE_PEAK_DIAG_13 rw — Voter override pos : Writing a 1'b1 in this register bit will force the peaking amp voter function to activate the voter pos signal for a single clock cycle.
  [28] RX_REE_PEAK_DIAG_12 rw — Voter override enable : Setting this bit to a 1'b1 will allow only the voter override pos and voter override neg bits in this register to control the voter in the peaking amp.
  [27:24] RX_REE_PEAK_DIAG_11_8 ro — Reserved
  [23:22] RX_REE_PEAK_DIAG_7_6 ro — Reserved
  [21:16] RX_REE_PEAK_DIAG_5_0 ro — Current peaking amp integrator accumulator: Current value of the tap integrator accumulator, without the unused sign bit.
  [15:14] RX_REE_PEAK_COVRD1_15_14 ro — Reserved
  [13:8] RX_REE_PEAK_COVRD1_13_8 rw — Peaking amp code override value mode 3: Value that will override the peaking amp code when in standard mode 3 when the peaking amp code override enable bit in the REE peaking amp diagnostics register on page 264 is active.
  [7:6] RX_REE_PEAK_COVRD1_7_6 ro — Reserved
  [5:0] RX_REE_PEAK_COVRD1_5_0 rw — Peaking amp code override value mode 2: Value that will override the peaking amp code when in standard mode 2 when the peaking amp code override enable bit in the REE peaking amp diagnostics register on page 264 is active.
0x8290 RX_REE_ATTEN_THR__RX_REE_ATTEN_CTRL_j reset 0xC020005 — REE attenuation control register Offset = 8290h + (j * 400h); where j = 0h to 3h
  [31:29] RX_REE_ATTEN_THR_15_13 ro — Reserved
  [28:24] RX_REE_ATTEN_THR_12_8 rw — Attenuation high threshold value: High threshold value to compare against the VGA gain accumulator value.
  [23:21] RX_REE_ATTEN_THR_7_5 ro — Reserved
  [20:16] RX_REE_ATTEN_THR_4_0 rw — Attenuation low threshold value: Low threshold value to compare against the VGA gain accumulator value.
  [15:5] RX_REE_ATTEN_CTRL_15_5 ro — Reserved
  [4:0] RX_REE_ATTEN_CTRL_4_0 rw — Receiver DFE attenuation maximum value: The maximum value the rxda_dfe_attenuation_bin will increase to.
0x8294 RX_REE_ATTEN_OVRD__RX_REE_ATTEN_CNT_j reset 0x2100 — REE attenuation counter register Offset = 8294h + (j * 400h); where j = 0h to 3h
  [31:25] RX_REE_ATTEN_OVRD_15_9 ro — Reserved
  [24] RX_REE_ATTEN_OVRD_8 rw — Attenuation override enable: Setting this bit to a 1'b1 will allow the rxda_dfe_attenuation_bin signal to be overridden by the attenuation override value signal in this register.
  [23:21] RX_REE_ATTEN_OVRD_7_5 ro — Reserved
  [20:16] RX_REE_ATTEN_OVRD_4_0 rw — Attenuation override value: When enabled by the attenuation override enable bit in this register, this value will override the current attenuation value on the rxda_dfe_attenuation_bin output pin, and also force a corresponding change on the rxda_dfe_attenuation_therm pin.
  [15:0] RX_REE_ATTEN_CNT_15_0 rw — Attenuation counter max: Value used to specify the maximum number of consecutive words above or below the specified thresholds which will result in triggering an increase or decrease in the rxda_dfe_attenuation_bin signal.
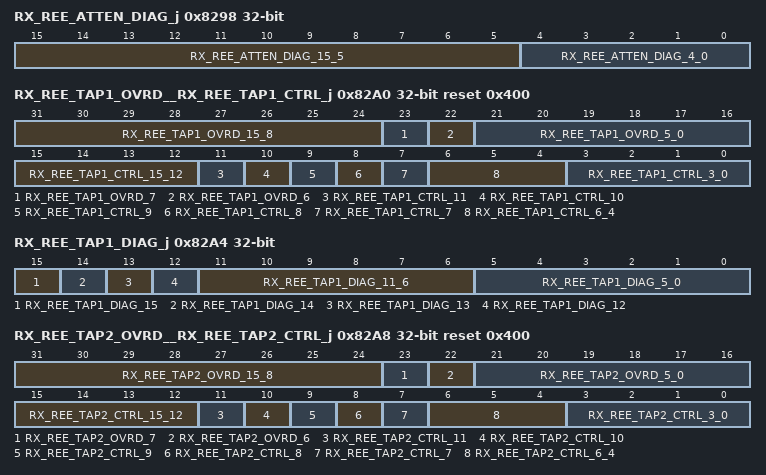
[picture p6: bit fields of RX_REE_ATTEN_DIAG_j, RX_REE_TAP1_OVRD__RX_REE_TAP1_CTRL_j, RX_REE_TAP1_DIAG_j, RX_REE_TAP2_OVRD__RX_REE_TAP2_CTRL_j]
0x8298 RX_REE_ATTEN_DIAG_j ro — REE attenuation diagnostics register Offset = 8298h + (j * 400h); where j = 0h to 3h
  [15:5] RX_REE_ATTEN_DIAG_15_5 — Reserved
  [4:0] RX_REE_ATTEN_DIAG_4_0 — Current attenuation value: Current value of the attenuation.
0x82A0 RX_REE_TAP1_OVRD__RX_REE_TAP1_CTRL_j reset 0x400 — REE tap 1 control register Offset = 82A0h + (j * 400h); where j = 0h to 3h
  [31:24] RX_REE_TAP1_OVRD_15_8 ro — Reserved
  [23] RX_REE_TAP1_OVRD_7 rw — Tap override enable: Setting this bit to a 1'b1 will enable the tap override field in this register to override the tap integrator accumulator functions.
  [22] RX_REE_TAP1_OVRD_6 ro — Reserved
  [21:16] RX_REE_TAP1_OVRD_5_0 rw — Tap override value: When the tap override enable bit in this register is active, the value in this field will override the integrator accumulator value, as well as the input to the binary to thermometer encoder.
  [15:12] RX_REE_TAP1_CTRL_15_12 ro — Reserved
  [11] RX_REE_TAP1_CTRL_11 rw — Tap coefficient combinational logic zero crossing enable:
  [10] RX_REE_TAP1_CTRL_10 rw — Tap coefficient combinational logic non zero crossing enable:
  [9] RX_REE_TAP1_CTRL_9 rw — Tap coefficient combinational logic bit 0 only enable:
  [8] RX_REE_TAP1_CTRL_8 rw — Receiver DFE tap coefficient disable: This bit disables the rxda_dfe_tap_coef output signal.
  [7] RX_REE_TAP1_CTRL_7 ro — Reserved
  [6:4] RX_REE_TAP1_CTRL_6_4 rw — Tap integrator accumulator scaler value: Specifies the amount to scale the input to the tap integrator accumulator by.
  [3:0] RX_REE_TAP1_CTRL_3_0 rw — Tap sigma delta accumulator scaler value: Specifies the amount to scale the input to the tap sigma delta accumulator by.
0x82A4 RX_REE_TAP1_DIAG_j — REE tap 1 diagnostics register Offset = 82A4h + (j * 400h); where j = 0h to 3h
  [15] RX_REE_TAP1_DIAG_15 ro — Reserved
  [14] RX_REE_TAP1_DIAG_14 rw — Voter override neg : Writing a 1'b1 in this register bit will force the tap voter function to activate the voter neg signal for a single clock cycle.
  [13] RX_REE_TAP1_DIAG_13 rw — Voter override pos : Writing a 1'b1 in this register bit will force the tap voter function to activate the voter pos signal for a single clock cycle.
  [12] RX_REE_TAP1_DIAG_12 rw — Voter override enable : Setting this bit to a 1'b1 will allow only the voter override pos and voter override neg bits in this register to control the voter in the tap.
  [11:6] RX_REE_TAP1_DIAG_11_6 ro — Reserved
  [5:0] RX_REE_TAP1_DIAG_5_0 ro — Current tap integrator accumulator: Current value of the tap integrator accumulator.
0x82A8 RX_REE_TAP2_OVRD__RX_REE_TAP2_CTRL_j reset 0x400 — REE tap 2 control register Offset = 82A8h + (j * 400h); where j = 0h to 3h
  [31:24] RX_REE_TAP2_OVRD_15_8 ro — Reserved
  [23] RX_REE_TAP2_OVRD_7 rw — Tap override enable: Setting this bit to a 1'b1 will enable the tap override field in this register to override the tap integrator accumulator functions.
  [22] RX_REE_TAP2_OVRD_6 ro — Reserved
  [21:16] RX_REE_TAP2_OVRD_5_0 rw — Tap override value: When the tap override enable bit in this register is active, the value in this field will override the integrator accumulator value, as well as the input to the binary to thermometer encoder.
  [15:12] RX_REE_TAP2_CTRL_15_12 ro — Reserved
  [11] RX_REE_TAP2_CTRL_11 rw — Tap coefficient combinational logic zero crossing enable:
  [10] RX_REE_TAP2_CTRL_10 rw — Tap coefficient combinational logic non zero crossing enable:
  [9] RX_REE_TAP2_CTRL_9 rw — Tap coefficient combinational logic bit 0 only enable:
  [8] RX_REE_TAP2_CTRL_8 rw — Receiver DFE tap coefficient disable: This bit disables the rxda_dfe_tap_coef output signal.
  [7] RX_REE_TAP2_CTRL_7 ro — Reserved
  [6:4] RX_REE_TAP2_CTRL_6_4 rw — Tap integrator accumulator scaler value: Specifies the amount to scale the input to the tap integrator accumulator by.
  [3:0] RX_REE_TAP2_CTRL_3_0 rw — Tap sigma delta accumulator scaler value: Specifies the amount to scale the input to the tap sigma delta accumulator by.
